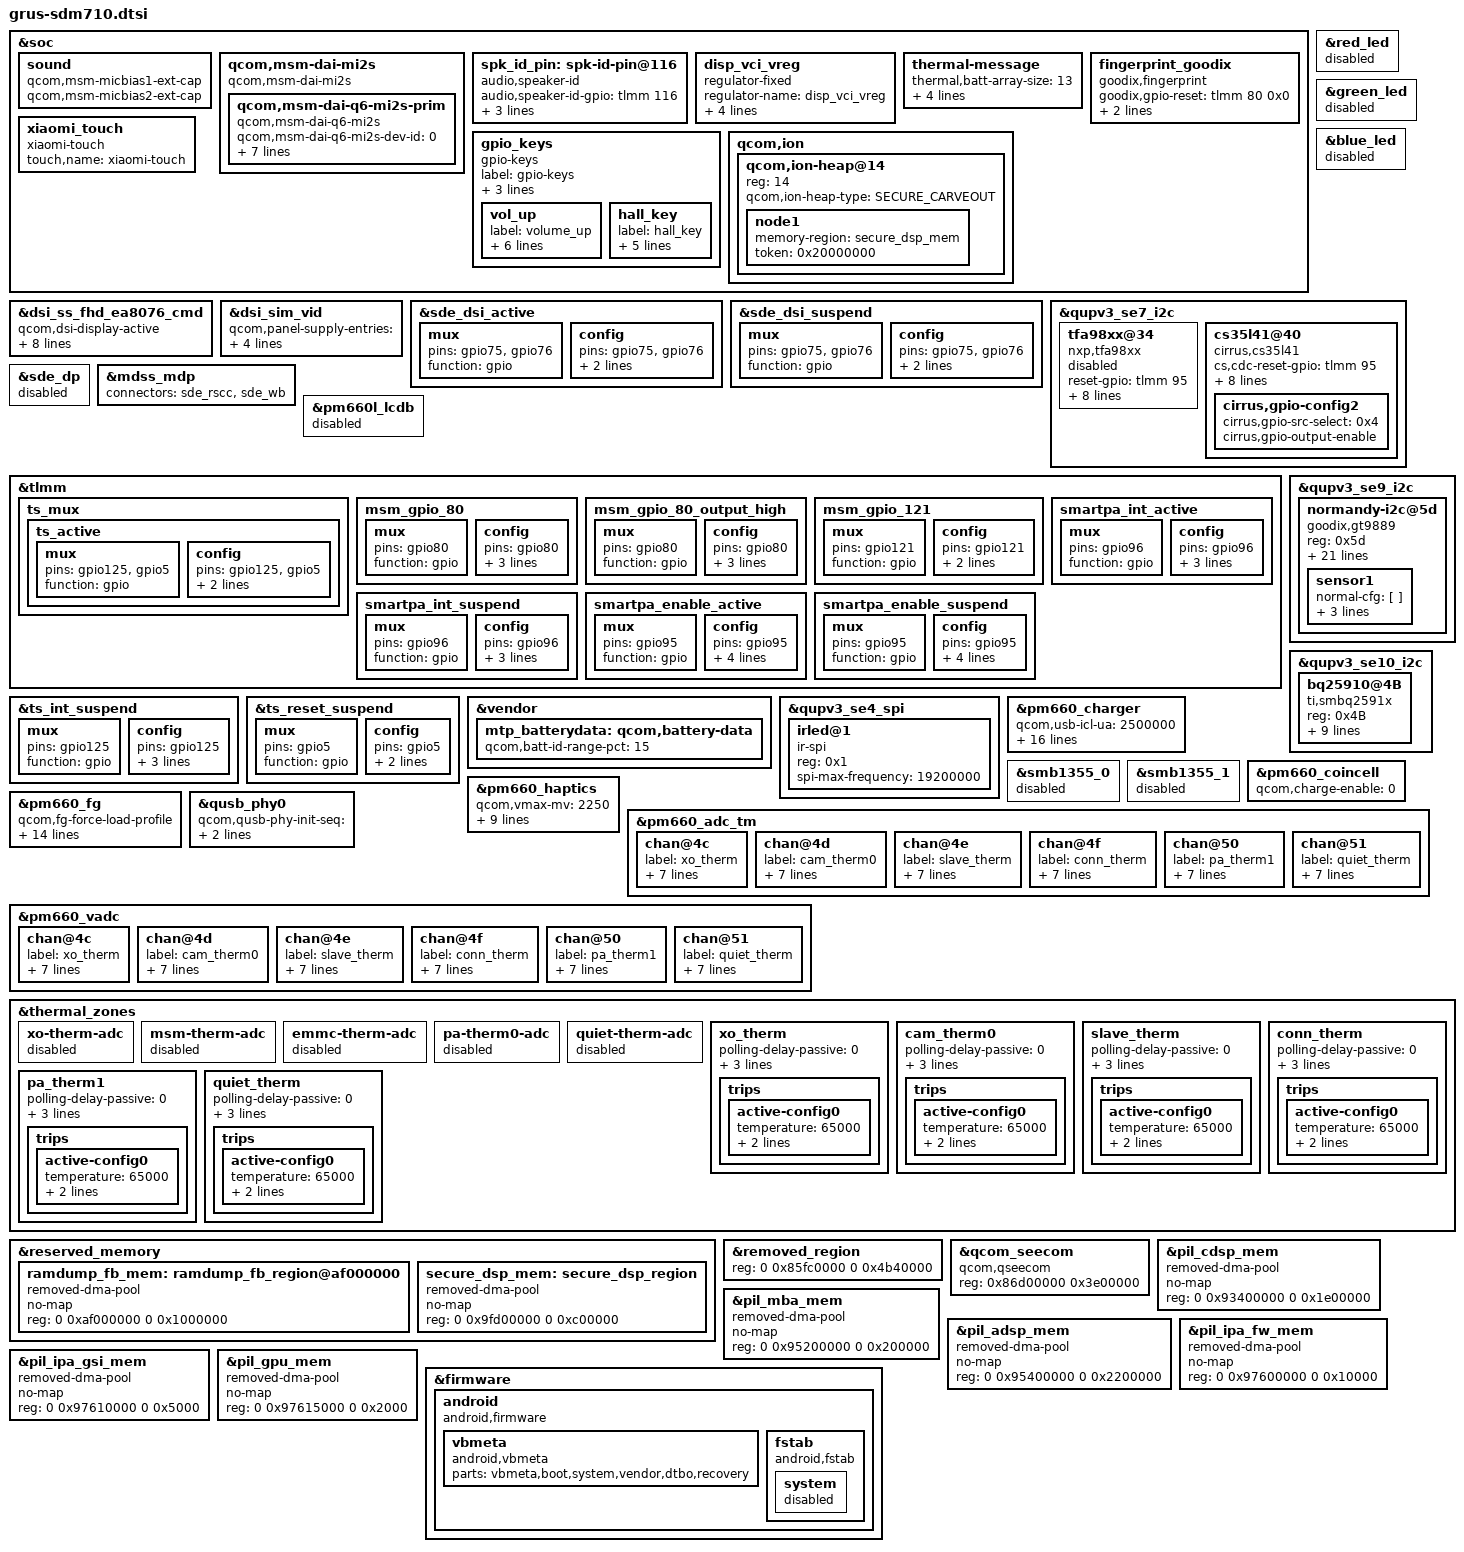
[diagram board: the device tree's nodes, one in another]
/* Copyright (c) 2017, The Linux Foundation. All rights reserved.
 * Copyright (C) 2019 XiaoMi, Inc.
 *
 * This program is free software; you can redistribute it and/or modify
 * it under the terms of the GNU General Public License version 2 and
 * only version 2 as published by the Free Software Foundation.
 *
 * This program is distributed in the hope that it will be useful,
 * but WITHOUT ANY WARRANTY; without even the implied warranty of
 * MERCHANTABILITY or FITNESS FOR A PARTICULAR PURPOSE.  See the
 * GNU General Public License for more details.
 */
#include "xiaomi-sdm710-common.dtsi"
#include "xiaomi-sde-display.dtsi"
#include "grus-sdm710-camera-sensor.dtsi"
&soc {
	sound {
		qcom,msm-micbias1-ext-cap;
		qcom,msm-micbias2-ext-cap;
	};

	qcom,msm-dai-mi2s {
		compatible = "qcom,msm-dai-mi2s";
		qcom,msm-dai-q6-mi2s-prim {
			compatible = "qcom,msm-dai-q6-mi2s";
			qcom,msm-dai-q6-mi2s-dev-id = <0>;
			qcom,msm-mi2s-rx-lines = <1>;
			qcom,msm-mi2s-tx-lines = <2>;
			pinctrl-names = "default", "sleep";
			pinctrl-0 = <&pri_mi2s_active
				&pri_mi2s_ws_active
				&pri_mi2s_sd0_active
				&pri_mi2s_sd1_active>;
			pinctrl-1 = <&pri_mi2s_sleep
				&pri_mi2s_ws_sleep
				&pri_mi2s_sd0_sleep
				&pri_mi2s_sd1_sleep>;
		};
	};

	spk_id_pin: spk-id-pin@116 {
		compatible = "audio,speaker-id";
		audio,speaker-id-gpio = <&tlmm 116 0>;
		pinctrl-names = "pull_down", "pull_up", "no_pull";
		pinctrl-0 = <&spk_id_pull_down>;
		pinctrl-1 = <&spk_id_pull_up>;
		pinctrl-2 = <&spk_id_no_pull>;
	};


	disp_vci_vreg: disp_vci_vreg {
                compatible = "regulator-fixed";
                regulator-name = "disp_vci_vreg";
                start-delay-us = <4000>;
                enable-active-high;
                regulator-boot-on;
		gpio = <&tlmm 76 0>;
        };

	thermal-message {
		thermal,batt-array-size = "13";
		thermal,batt-level-screen-on = "0 2 4 6 8 8 9 12 13 14 14 14 16";
		thermal,batt-level-screen-off = "0 0 0 0 4 4 4 5 6 8 9 14 16";
	};

	fingerprint_goodix {
		compatible = "goodix,fingerprint";
		goodix,gpio-reset = <&tlmm 80 0x0>;
		goodix,gpio-irq = <&tlmm 121 0x0>;
		fp-gpio-pwr = <&tlmm 99 0>;
		status = "ok";
	};
};

&soc {
        gpio_keys {
                compatible = "gpio-keys";
                label = "gpio-keys";

                pinctrl-names = "default";
                pinctrl-0 = <&key_cam_snapshot_default
                             &key_cam_focus_default
                             &key_vol_up_default
                             &key_hall_default>;

                vol_up {
                        label = "volume_up";
                        gpios = <&pm660l_gpios 7 GPIO_ACTIVE_LOW>;
                        linux,input-type = <1>;
                        linux,code = <115>;
                        gpio-key,wakeup;
                        debounce-interval = <15>;
                        linux,can-disable;
                };
                hall_key {
                        label = "hall_key";
                        gpios = <&tlmm 124 GPIO_ACTIVE_LOW>;
                        linux,input-type = <5>;
                        linux,code = <0>;
                        gpio-key,wakeup;
                        debounce-interval = <15>;
                };
        };
		xiaomi_touch {
			compatible = "xiaomi-touch";
			status = "ok";
			touch,name = "xiaomi-touch";
		};
};

&dsi_ss_fhd_ea8076_cmd {
	qcom,dsi-display-active;
	qcom,panel-supply-entries = <&dsi_amoled_panel_pwr_supply>;
	qcom,mdss-dsi-bl-pmic-control-type = "bl_ctrl_dcs";
	qcom,mdss-dsi-bl-min-level = <2>;
	qcom,mdss-dsi-bl-max-level = <2047>;
	qcom,platform-reset-gpio = <&tlmm 75 0>;
	qcom,platform-te-gpio = <&tlmm 10 0>;
};

&dsi_sim_vid {
	qcom,panel-supply-entries = <&dsi_panel_pwr_supply>;
	qcom,mdss-dsi-bl-pmic-control-type = "bl_ctrl_dcs";
	qcom,platform-reset-gpio = <&tlmm 75 0>;
};

&sde_dsi_active {
	mux {
		pins = "gpio75", "gpio76";
		function = "gpio";
	};

	config {
		pins = "gpio75", "gpio76";
		drive-strength = <8>;	/* 8 mA */
		bias-disable = <0>;   /* no pull */
	};
};

&sde_dsi_suspend {
	mux {
		pins = "gpio75", "gpio76";
		function = "gpio";
	};

	config {
		pins = "gpio75", "gpio76";
		drive-strength = <2>;	/* 2 mA */
		bias-pull-down; 		/* PULL DOWN */
	};
};

&red_led {
	status = "disabled";
};

&green_led {
	status = "disabled";
};

&blue_led {
	status = "disabled";
};

&qupv3_se7_i2c {
	status = "ok";

	tfa98xx@34 {
		status = "disabled";
		compatible = "nxp,tfa98xx";
		reset-gpio = <&tlmm 95 0>;
		irq-gpio = <&tlmm 96 0>;
		interrupt-parent = <&tlmm>;
		interrupts = <96 0>;
		interrupt-names = "smartpa_irq";
		pinctrl-names = "default", "sleep";
		pinctrl-0 = <&smartpa_int_active &smartpa_enable_active>;
		pinctrl-1 = <&smartpa_int_suspend &smartpa_enable_suspend>;
		reg = <0x34>;
	};

	cs35l41@40 {
		status = "ok";
		compatible = "cirrus,cs35l41";
		cs,cdc-reset-gpio = <&tlmm 95 0>;
		reg = <0x40>;
		pinctrl-names = "cs35l41_irq_default";
		pinctrl-0 = <&smartpa_int_active>;
		interrupt-parent = <&tlmm>;
		interrupts = <96 0>;

		cirrus,temp-warn_threshold = <3>;
		cirrus,boost-peak-milliamp = <4000>;
		cirrus,boost-ind-nanohenry = <1000>;
		cirrus,boost-cap-microfarad = <15>;
		cirrus,gpio-config2 {
			cirrus,gpio-src-select = <0x4>;
			cirrus,gpio-output-enable;
		};
	};
};

&sde_dp {
	status = "disabled";
};

&mdss_mdp {
	connectors = <&sde_rscc &sde_wb>;
};

&pm660l_lcdb {
	status = "disabled";
};

/*redefine pinctrl stat for grus*/
&tlmm {
	ts_mux {
		ts_active: ts_active {
			mux {
				pins = "gpio125", "gpio5";
				function = "gpio";
			};

			config {
				pins = "gpio125", "gpio5";
				drive-strength = <16>;
				bias-pull-up;
			};
		};
	};
};

&ts_int_suspend {
	mux {
		pins = "gpio125";
		function = "gpio";
	};

	config {
		pins = "gpio125";
		drive-strength = <16>;
		bias-diable;
		input-enable;
	};

};

&ts_reset_suspend {
	mux {
		pins = "gpio5";
		function = "gpio";
	};

	config {
		pins = "gpio5";
		drive-strength = <16>;
		bias-disable;
	};
};




&qupv3_se9_i2c {
		status = "ok";
		normandy-i2c@5d {
			compatible = "goodix,gt9889";
			reg = <0x5d>;
			status = "ok";
			interrupt-parent = <&tlmm>;
			interrupts = <125 0x2800>;
			vtouch-supply = <&pm660l_l8>;
			iotouch-supply = <&pm660_l13>;
			vtouch-load = <600000>;
			pinctrl-names = "pmx_ts_active","pmx_ts_suspend";
			pinctrl-0 = <&ts_active>;
			pinctrl-1 = <&ts_int_suspend &ts_reset_suspend>;
			goodix,reset-gpio = <&tlmm 5 0x0>;
			goodix,irq-gpio = <&tlmm 125 0x2800>;
			goodix,irq-flags = <2>; /* 1:trigger rising, 2:trigger falling;*/
			goodix,panel-max-id = <10>;
			goodix,panel-max-x = <1079>;
			goodix,panel-max-y = <2339>;
			goodix,panel-max-w = <127>;
			goodix,panel-max-p = <127>;
			goodix,panel-max-fod = <127>;
	/*		goodix,panel-key-map = <158 172 217>; */ /*KEY_BACK, KEY_HOMEPAGE, KEY_SEARCH*/
			goodix,power-on-delay-us = <300000>; /*300ms*/
			goodix,power-off-delay-us = <5000>;
			goodix,cfg-name = "goodix_gt9886_cfg_f2.bin";
	/*		goodix,swap-axis; */
			goodix,x2x;
			goodix,y2y;
	/*		goodix,pen-enable; */
	/*		goodix,key-of-pen = <331 332>; */ /*BTN_STYLUS, BTN_STYLUS2*/
			sensor1 {
					normal-cfg = [
					];
					goodix,fw-name = "goodix_gt9886_fw_f2.bin";
					goodix,limit-name = "goodix_gt9886_limit_f2.tporder";
			};
		};
};

&qupv3_se10_i2c {
	status = "ok";
	bq25910@4B {
		compatible = "ti,smbq2591x";
		reg = <0x4B>;

		interrupt-parent = <&tlmm>;
		interrupts = <54 IRQ_TYPE_EDGE_FALLING>;
		interrupt-names = "bq2591x_irq";

		qcom,chg-vadc = <&pm660_vadc>;

		/*ti,bq2591x,enable-term;*/
		ti,bq2591x,charge-voltage = <4400>;
		ti,bq2591x,charge-current = <3000>;
		ti,bq2591x,input-current-limit = <3000>;
		ti,bq2591x,input-voltage-limit = <4500>;
		ti,bq2591x,vbatlow-volt = <3500>;
		ti,bq2591x,term-current = <500>;
	};
};

&tlmm {
	/* GPIO_80 : FP_RESET_N */
	msm_gpio_80: msm_gpio_80 {
		mux {
			 pins = "gpio80";
			 function = "gpio";
		};

		config {
			pins = "gpio80";
			drive-strength = <2>;
			bias-disable;
			output-low;
		};
	};

	/* GPIO_80 : FP_RESET_N, state device active*/
	msm_gpio_80_output_high: msm_gpio_80_output_high {
		mux {
			pins = "gpio80";
			function = "gpio";
		};

		config {
			pins = "gpio80";
			drive-strength = <2>;
			bias-disable;
			output-high;
		};
	};

	/* GPIO_121 : FP_INT_N */
	msm_gpio_121: msm_gpio_121 {
		mux {
			pins = "gpio121";
			function = "gpio";
		};

		config {
			pins = "gpio121";
			drive-strength = <2>;
			bias-pull-down;
		};
    };

	/* GPIO_96 : SPKR_INT */
	smartpa_int_active: smartpa_int_active {
		/* active state */
		mux {
			/* GPIO 96 Interrupt */
			pins = "gpio96";
			function = "gpio";
		};

		config {
			pins = "gpio96";
			drive-strength = <2>; /* 2 MA */
			bias-pull-up;
			input-enable;
		};
	};

	/* GPIO_96 : SPKR_INT */
	smartpa_int_suspend: smartpa_int_suspend {
		/* sleep state */
		mux {
			/* GPIO 96 Interrupt */
			pins = "gpio96";
			function = "gpio";
		};

		config {
			pins = "gpio96";
			drive-strength = <2>; /* 2 MA */
			bias-pull-up;
			input-enable;
		};
	};

	/* GPIO_95 : SPKR_PA_RST */
	smartpa_enable_active: smartpa_enable_active {
		/* active state */
		mux {
			/* GPIO 95 rst pin */
			pins = "gpio95";
			function = "gpio";
		};

		config {
			pins = "gpio95";
			drive-strength = <2>;
			bias-disable;
			bias-pull-down;
			output-low;
		};
	};

	/* GPIO_95 : SPKR_PA_RST */
	smartpa_enable_suspend: smartpa_enable_suspend {
		/* sleep state */
		mux {
			/* GPIO 95 rst pin */
			pins = "gpio95";
			function = "gpio";
		};

		config {
			pins = "gpio95";
			drive-strength = <2>;
			bias-disable;
			bias-pull-down;
			output-low;
		};
	};
};

&vendor {
	mtp_batterydata: qcom,battery-data {
		qcom,batt-id-range-pct = <15>;
		#include "batterydata-f2-scud-3070mAh.dtsi"
		#include "batterydata-f2-coslight-3070mAh.dtsi"
	};
};

&soc {
	qcom,ion {
		qcom,ion-heap@14 {
			reg = <14>;
			qcom,ion-heap-type = "SECURE_CARVEOUT";
			node1 {
				memory-region = <&secure_dsp_mem>;
				token = <0x20000000>; /* ION_FLAG_CP_CDSP */
			};
		};
	};
};

&qupv3_se4_spi {
	status = "ok";
	irled@1 {
		compatible = "ir-spi";
		reg = <0x1>;
		status = "ok";
		spi-max-frequency = <19200000>;
	};
};

&pm660_charger {
	qcom,usb-icl-ua = <2500000>;
	qcom,fcc-max-ua = <2950000>;
	qcom,fcc-low-temp-delta = <2700000>;
	qcom,fcc-hot-temp-delta = <1500000>;
	qcom,fcc-cool-temp-delta = <2100000>;
	qcom,auto-recharge-soc;
	qcom,sw-jeita-enable;
	qcom,thermal-mitigation
				= <1800000 1600000 1400000 1200000 1000000 1000000 1000000>;
	qcom,thermal-mitigation-dcp
				= <1800000 1800000 1800000 1800000 1800000 1800000 1800000
				1800000 1800000 1800000 1800000 1800000 1600000 1400000
				1200000 1000000>;
	qcom,thermal-mitigation-qc3
				= <2500000 2400000 2350000 2200000 2075000 1925000 1825000
				1650000 1500000 1375000 1225000 1100000 975000 825000
				675000 475000>;
	qcom,thermal-mitigation-qc2
				= <1625000 1625000 1625000 1625000 1625000 1525000 1425000
				1325000 1225000 1125000 10255000 925000 825000 725000
				625000 525000>;
	qcom,thermal-mitigation-pd-base
				= <3000000 2800000 2600000 2400000 2200000 2000000 1800000
				1600000 1600000 1400000 1200000 1100000 1000000 900000
				752500 525000>;
};

&smb1355_0 {
	status = "disabled";
};

&smb1355_1 {
	status = "disabled";
};


&pm660_coincell{
	qcom,charge-enable = <0>;
};

&pm660_haptics {
	qcom,vmax-mv = <2250>;
	qcom,lra-auto-mode;
	qcom,wave-play-rate-us = <5181>;
	qcom,wave-shape = "sine";
	qcom,lra-high-z = "opt1";
	qcom,lra-auto-res-mode = "none";
	qcom,lra-res-cal-period = <4>;
	qcom,effect-max = <4>;
	qcom,effect-arry = [3e 3e 2f be 00 00 00 00
	3e 3e 3e 3f be 88 00 00
	3e 3e 3e 3f be 88 00 00
	3f 3f 3f 3f 3f 3f be 88];
	status = "okay";
};

&pm660_fg {
	qcom,fg-force-load-profile;
	qcom,fg-sys-term-current = <(-300)>;
	qcom,fg-chg-term-current = <200>;
	qcom,fg-auto-recharge-soc;
	qcom,fg-recharge-soc-thr = <99>;
	qcom,fg-cutoff-voltage = <3400>;
	qcom,fg-empty-voltage = <3100>;
	qcom,fg-cutoff-current = <200>;
	qcom,fg-jeita-hyst-temp = <1>;
	qcom,fg-jeita-thresholds = <0 15 45 60>;
	qcom,fg-esr-clamp-mohms = <60>;
	qcom,fg-batt-temp-delta = <6>;
	qcom,slope-limit-temp-threshold = <100>;
	qcom,slope-limit-coeffs = <10 11 12 13>;
	qcom,battery-data = <&mtp_batterydata>;
};

&qusb_phy0 {
                qcom,qusb-phy-init-seq =
                        /* <value reg_offset> */
                           <0x23 0x210 /* PWR_CTRL1 */
                            0x03 0x04  /* PLL_ANALOG_CONTROLS_TWO */
                            0x7c 0x18c /* PLL_CLOCK_INVERTERS */
                            0x80 0x2c  /* PLL_CMODE */
                            0x0a 0x184 /* PLL_LOCK_DELAY */
                            0x19 0xb4  /* PLL_DIGITAL_TIMERS_TWO */
                            0x40 0x194 /* PLL_BIAS_CONTROL_1 */
                            0x20 0x198 /* PLL_BIAS_CONTROL_2 */
                            0x21 0x214 /* PWR_CTRL2 */
                            0x08 0x220 /* IMP_CTRL1 */
                            0x58 0x224 /* IMP_CTRL2 */
                            0x07 0x240 /* TUNE1 */
                            0x29 0x244 /* TUNE2 */
                            0xca 0x248 /* TUNE3 */
                            0x04 0x24c /* TUNE4 */
                            0x03 0x250 /* TUNE5 */
                            0x00 0x23c /* CHG_CTRL2 */
                            0x22 0x210>; /* PWR_CTRL1 */
		mi,efuse-pll-bias;
};

&pm660_adc_tm {
	chan@4c {
		label = "xo_therm";
		reg = <0x4c>;
		qcom,pre-div-channel-scaling = <0>;
		qcom,calibration-type = "ratiometric";
		qcom,scale-function = <4>;
		qcom,hw-settle-time = <2>;
		qcom,btm-channel-number = <0x78>;
		qcom,thermal-node;
	};

	chan@4d {
		label = "cam_therm0";
		reg = <0x4d>;
		qcom,pre-div-channel-scaling = <0>;
		qcom,calibration-type = "ratiometric";
		qcom,scale-function = <2>;
		qcom,hw-settle-time = <2>;
		qcom,btm-channel-number = <0x68>;
		qcom,thermal-node;
	};

	chan@4e {
		label = "slave_therm";
		reg = <0x4e>;
		qcom,pre-div-channel-scaling = <0>;
		qcom,calibration-type = "ratiometric";
		qcom,scale-function = <2>;
		qcom,hw-settle-time = <2>;
		qcom,btm-channel-number = <0x80>;
		qcom,thermal-node;
	};

	chan@4f {
		label = "conn_therm";
		reg = <0x4f>;
		qcom,pre-div-channel-scaling = <0>;
		qcom,calibration-type = "ratiometric";
		qcom,scale-function = <2>;
		qcom,hw-settle-time = <2>;
		qcom,btm-channel-number = <0x88>;
		qcom,thermal-node;
	};

	chan@50 {
		label = "pa_therm1";
		reg = <0x50>;
		qcom,pre-div-channel-scaling = <0>;
		qcom,calibration-type = "ratiometric";
		qcom,scale-function = <2>;
		qcom,hw-settle-time = <2>;
		qcom,btm-channel-number = <0x90>;
		qcom,thermal-node;
	};

	chan@51 {
		label = "quiet_therm";
		reg = <0x51>;
		qcom,pre-div-channel-scaling = <0>;
		qcom,calibration-type = "ratiometric";
		qcom,scale-function = <2>;
		qcom,hw-settle-time = <2>;
		qcom,btm-channel-number = <0x70>;
		qcom,thermal-node;
	};
};

&pm660_vadc {
	chan@4c {
		label = "xo_therm";
		reg = <0x4c>;
		qcom,decimation = <2>;
		qcom,pre-div-channel-scaling = <0>;
		qcom,calibration-type = "ratiometric";
		qcom,scale-function = <4>;
		qcom,hw-settle-time = <2>;
		qcom,fast-avg-setup = <0>;
	};

	chan@4d {
		label = "cam_therm0";
		reg = <0x4d>;
		qcom,decimation = <2>;
		qcom,pre-div-channel-scaling = <0>;
		qcom,calibration-type = "ratiometric";
		qcom,scale-function = <2>;
		qcom,hw-settle-time = <2>;
		qcom,fast-avg-setup = <0>;
	};

	chan@4e {
		label = "slave_therm";
		reg = <0x4e>;
		qcom,decimation = <2>;
		qcom,pre-div-channel-scaling = <0>;
		qcom,calibration-type = "ratiometric";
		qcom,scale-function = <2>;
		qcom,hw-settle-time = <2>;
		qcom,fast-avg-setup = <0>;
	};

	chan@4f {
		label = "conn_therm";
		reg = <0x4f>;
		qcom,decimation = <2>;
		qcom,pre-div-channel-scaling = <0>;
		qcom,calibration-type = "ratiometric";
		qcom,scale-function = <2>;
		qcom,hw-settle-time = <2>;
		qcom,fast-avg-setup = <0>;
	};

	chan@50 {
		label = "pa_therm1";
		reg = <0x50>;
		qcom,decimation = <2>;
		qcom,pre-div-channel-scaling = <0>;
		qcom,calibration-type = "ratiometric";
		qcom,scale-function = <2>;
		qcom,hw-settle-time = <2>;
		qcom,fast-avg-setup = <0>;
	};

	chan@51 {
		label = "quiet_therm";
		reg = <0x51>;
		qcom,decimation = <2>;
		qcom,pre-div-channel-scaling = <0>;
		qcom,calibration-type = "ratiometric";
		qcom,scale-function = <2>;
		qcom,hw-settle-time = <2>;
		qcom,fast-avg-setup = <0>;
	};
};

&thermal_zones {
	xo-therm-adc {
		status = "disabled";
	};

	msm-therm-adc {
		status = "disabled";
	};

	emmc-therm-adc {
		status = "disabled";
	};

	pa-therm0-adc {
		status = "disabled";
	};

	quiet-therm-adc {
		status = "disabled";
	};

	xo_therm {
		polling-delay-passive = <0>;
		polling-delay = <0>;
		thermal-sensors = <&pm660_adc_tm 0x4c>;
		thermal-governor = "user_space";

		trips {
			active-config0 {
				temperature = <65000>;
				hysteresis = <1000>;
				type = "passive";
			};
		};
	};

	cam_therm0 {
		polling-delay-passive = <0>;
		polling-delay = <0>;
		thermal-sensors = <&pm660_adc_tm 0x4d>;
		thermal-governor = "user_space";

		trips {
			active-config0 {
				temperature = <65000>;
				hysteresis = <1000>;
				type = "passive";
			};
		};
	};

	slave_therm {
		polling-delay-passive = <0>;
		polling-delay = <0>;
		thermal-sensors = <&pm660_adc_tm 0x4e>;
		thermal-governor = "user_space";

		trips {
			active-config0 {
				temperature = <65000>;
				hysteresis = <1000>;
				type = "passive";
			};
		};
	};

	conn_therm {
		polling-delay-passive = <0>;
		polling-delay = <0>;
		thermal-sensors = <&pm660_adc_tm 0x4f>;
		thermal-governor = "user_space";

		trips {
			active-config0 {
				temperature = <65000>;
				hysteresis = <1000>;
				type = "passive";
			};
		};
	};

	pa_therm1 {
		polling-delay-passive = <0>;
		polling-delay = <0>;
		thermal-sensors = <&pm660_adc_tm 0x50>;
		thermal-governor = "user_space";

		trips {
			active-config0 {
				temperature = <65000>;
				hysteresis = <1000>;
				type = "passive";
			};
		};
	};

	quiet_therm {
		polling-delay-passive = <0>;
		polling-delay = <0>;
		thermal-sensors = <&pm660_adc_tm 0x51>;
		thermal-governor = "user_space";

		trips {
			active-config0 {
				temperature = <65000>;
				hysteresis = <1000>;
				type = "passive";
			};
		};
	};
};

&reserved_memory {
	ramdump_fb_mem: ramdump_fb_region@af000000 {
		compatible = "removed-dma-pool";
		no-map;
		reg = <0 0xaf000000 0 0x1000000>;
	};

	secure_dsp_mem: secure_dsp_region {
		compatible = "removed-dma-pool";
		no-map;
		reg = <0 0x9fd00000 0 0xc00000>;
	};
};

&removed_region {
	reg = <0 0x85fc0000 0 0x4b40000>;
};

&qcom_seecom {
	compatible = "qcom,qseecom";
	reg = <0x86d00000 0x3e00000>;
};

&pil_cdsp_mem {
	compatible = "removed-dma-pool";
	no-map;
	reg = <0 0x93400000 0 0x1e00000>;
};

&pil_mba_mem {
	compatible = "removed-dma-pool";
	no-map;
	reg = <0 0x95200000 0 0x200000>;
};

&pil_adsp_mem {
	compatible = "removed-dma-pool";
	no-map;
	reg = <0 0x95400000 0 0x2200000>;
};

&pil_ipa_fw_mem {
	compatible = "removed-dma-pool";
	no-map;
	reg = <0 0x97600000 0 0x10000>;
};

&pil_ipa_gsi_mem {
	compatible = "removed-dma-pool";
	no-map;
	reg = <0 0x97610000 0 0x5000>;
};

&pil_gpu_mem {
	compatible = "removed-dma-pool";
	no-map;
	reg = <0 0x97615000 0 0x2000>;
};

&firmware {
	android {
		compatible = "android,firmware";
		vbmeta {
			compatible = "android,vbmeta";
			parts = "vbmeta,boot,system,vendor,dtbo,recovery";
		};

		fstab {
			compatible = "android,fstab";
			system {
				status = "disabled";
			};
		};
	};
};
